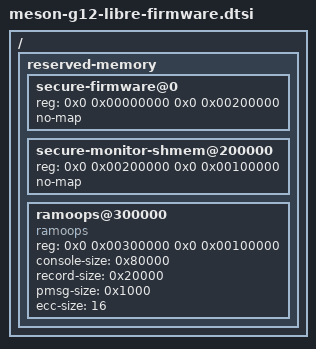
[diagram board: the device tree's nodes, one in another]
// SPDX-License-Identifier: (GPL-2.0+ OR MIT)
/*
 * Copyright (c) 2026 Libre Computer
 *
 * G12A / G12B / SM1 firmware reservations for the LIBRE boot chain (our
 * TF-A with the low-16 MiB secure layout). A board .dts includes exactly one
 * of this file or meson-g12-vendor-firmware.dtsi, after its SoC .dtsi.
 *
 * The block is the first 16 MiB of DRAM, and these are the same three nodes,
 * in the same order and with the same properties, that U-Boot's
 * meson_add_libre_secure_reservation() (arch/arm/mach-meson/board-g12a.c)
 * writes into the booted blob under CONFIG_MESON_G12A_LIBRE_SECURE_LAYOUT.
 * Every value is a G12A_LIBRE_* constant of
 * arch/arm/include/asm/arch-meson/g12a.h in the u-boot tree:
 *
 *   secure-firmware@0            base G12A_LIBRE_BLOCK_BASE      0x00000000
 *                                size G12A_LIBRE_SECURE_SIZE     0x00200000
 *                                     (= SHARED_BASE - BLOCK_BASE, 2 MiB)
 *                                no-map. BL31; there is no ROM mirror on
 *                                this family, the first MiB is held to keep
 *                                the map GXL's.
 *
 *   secure-monitor-shmem@200000  base G12A_LIBRE_SHARED_BASE     0x00200000
 *                                size G12A_LIBRE_SHARED_SIZE     0x00100000
 *                                no-map. The SMC mailboxes are NON-secure,
 *                                but meson_sm_map_shmem() maps them with
 *                                ioremap_cache(), which arm64 refuses on a
 *                                page in the linear map.
 *
 *   ramoops@300000               base G12A_LIBRE_RAMOOPS_BASE    0x00300000
 *                                size G12A_LIBRE_RAMOOPS_SIZE    0x00100000
 *                                MAPPED (no no-map), as board-g12a.c writes
 *                                it. Zone sizes G12A_LIBRE_RAMOOPS_{CONSOLE,
 *                                RECORD,PMSG,ECC}_SIZE = 0x80000 / 0x20000 /
 *                                0x1000 / 16.
 *
 * 0x00400000 + 12 MiB is the OPTIONAL OP-TEE band. It is not described here:
 * it is ordinary memory unless OP-TEE runs, and U-Boot adds
 * reserved-memory/optee-core@400000 and firmware/optee at boot when it does
 * (amlogic/software/boot/design/libre-secure-block-and-optee.md).
 *
 * This file replaces meson-libretech-ramoops.dtsi (ramoops@7400000) on a
 * libre board: that address is derived from the vendor layout, and the libre
 * first stage's DRAM tests overwrite it on every boot.
 */

/ {
	reserved-memory {
		secure-firmware@0 {
			reg = <0x0 0x00000000 0x0 0x00200000>;	/* 2 MiB */
			no-map;
		};

		secure-monitor-shmem@200000 {
			reg = <0x0 0x00200000 0x0 0x00100000>;	/* 1 MiB */
			no-map;
		};

		ramoops@300000 {
			compatible = "ramoops";
			reg = <0x0 0x00300000 0x0 0x00100000>;	/* 1 MiB */
			console-size = <0x80000>;
			record-size = <0x20000>;
			pmsg-size = <0x1000>;
			ecc-size = <16>;
		};
	};
};
